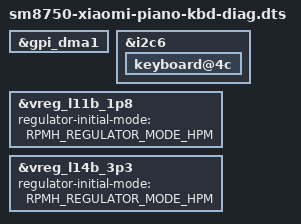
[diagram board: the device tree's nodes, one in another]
// SPDX-License-Identifier: BSD-3-Clause
/*
 * Supervised keyboard bridge diagnostic variant of the piano board.
 *
 * Enables only I2C6 with the Nanosic bridge, and the GPI DMA provider the
 * GENI I2C driver needs when firmware has disabled the SE FIFO. Both bridge
 * rails get the stock HPM initial mode. The driver loads the stock MCU
 * application into the bridge RAM and keeps it awake while bound; runtime
 * and system PM are not implemented. Not for default or unattended boots.
 */

#include "sm8750-xiaomi-piano.dts"

&gpi_dma1 {
	status = "okay";
};

&i2c6 {
	status = "okay";

	keyboard@4c {
		status = "okay";
	};
};

&vreg_l11b_1p8 {
	regulator-initial-mode = <RPMH_REGULATOR_MODE_HPM>;
};

&vreg_l14b_3p3 {
	regulator-initial-mode = <RPMH_REGULATOR_MODE_HPM>;
};
